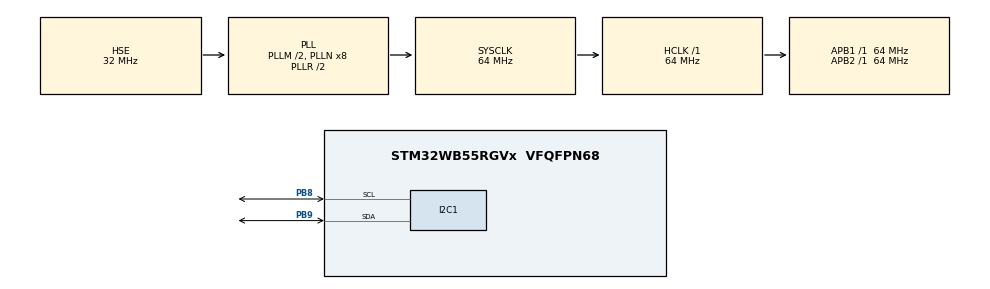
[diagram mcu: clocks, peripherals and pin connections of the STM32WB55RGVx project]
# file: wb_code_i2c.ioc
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I2C1.OwnAddress=0x13
I2C1.Timing=0x10B17DB5
Mcu.Family=STM32WB
Mcu.Name=STM32WB55RGVx
Mcu.Package=VFQFPN68
NVIC.PriorityGroup=NVIC_PRIORITYGROUP_4
OSC_IN.GPIO_Label=RCC_OSC_IN
OSC_IN.Mode=HSE-External-Oscillator
OSC_IN.Signal=RCC_OSC_IN
OSC_OUT.GPIO_Label=RCC_OSC_OUT
OSC_OUT.Mode=HSE-External-Oscillator
OSC_OUT.Signal=RCC_OSC_OUT
P-NUCLEO-WB55-NUCLEO.BUTTON=1
P-NUCLEO-WB55-NUCLEO.BUTTON2=1
P-NUCLEO-WB55-NUCLEO.BUTTON3=1
P-NUCLEO-WB55-NUCLEO.LD1=true
P-NUCLEO-WB55-NUCLEO.LD2=true
P-NUCLEO-WB55-NUCLEO.LD3=true
P-NUCLEO-WB55-NUCLEO.VCP=true
PA11.GPIO_Label=USB_DM
PA11.Signal=USB_DM
PA12.GPIO_Label=USB_DP
PA12.Signal=USB_DP
PA13.GPIO_Label=JTMS
PA13.Mode=Serial_Wire
PA13.Signal=SYS_JTMS-SWDIO
PA14.GPIO_Label=JTCK
PA14.Mode=Serial_Wire
PA14.Signal=SYS_JTCK-SWCLK
PB3.GPIO_Label=JTDO
PB3.Signal=SYS_JTDO-SWO
PB6.Signal=USART1_TX
PB7.Signal=USART1_RX
PB8.Mode=I2C
PB8.Signal=I2C1_SCL
PB9.Mode=I2C
PB9.Signal=I2C1_SDA
PC13.GPIO_Label=SYS_WKUP2
PC13.Signal=SYS_WKUP2
PC14-OSC32_IN.GPIO_Label=RCC_OSC32_IN
PC14-OSC32_IN.Mode=LSE-External-Oscillator
PC14-OSC32_IN.Signal=RCC_OSC32_IN
PC15-OSC32_OUT.GPIO_Label=RCC_OSC32_OUT
PC15-OSC32_OUT.Mode=LSE-External-Oscillator
PC15-OSC32_OUT.Signal=RCC_OSC32_OUT
ProjectManager.HeapSize=0x200
ProjectManager.StackSize=0x400
ProjectManager.TargetToolchain=STM32CubeIDE
RCC.ADCFreq_Value=64000000
RCC.AHB2CLKDivider=RCC_SYSCLK_DIV2
RCC.AHBFreq_Value=64000000
RCC.APB1Freq_Value=64000000
RCC.APB1TimFreq_Value=64000000
RCC.APB2Freq_Value=64000000
RCC.APB2TimFreq_Value=64000000
RCC.APB3Freq_Value=16000000
RCC.Cortex2_Div=SYSTICK_CLKSOURCE_HCLK_DIV8
RCC.CortexFreq_Value=64000000
RCC.HCLKFreq_Value=64000000
RCC.HSE_VALUE=32000000
RCC.HSI48_VALUE=48000000
RCC.HSI_VALUE=16000000
RCC.PLLM=RCC_PLLM_DIV2
RCC.PLLSourceVirtual=RCC_PLLSOURCE_HSE
RCC.SMPSCLockSelection=RCC_SMPSCLKSOURCE_HSI
RCC.SMPSCLockSelectionVirtual=RCC_SMPSCLKSOURCE_HSI
RCC.SMPSCLockSelectionVirtualVirtual=RCC_SMPSCLKSOURCE_HSI
RCC.SMPSDivider=1
RCC.SYSCLKFreq_VALUE=64000000
RCC.SYSCLKSource=RCC_SYSCLKSOURCE_PLLCLK
RCC.USBFreq_Value=64000000
RCC.VCOOutputFreq_Value=128000000
VP_MEMORYMAP_VS_MEMORYMAP.Mode=CurAppReg
VP_P-NUCLEO-WB55-NUCLEO_VS_BSP_COMMON.Mode=COMMON
board=P-NUCLEO-WB55-NUCLEO

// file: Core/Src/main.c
/* USER CODE BEGIN Header */
/**
  ******************************************************************************
  * @file           : main.c
  * @brief          : Main program body
  ******************************************************************************
  * @attention
  *
  * Copyright (c) 2025 STMicroelectronics.
  * All rights reserved.
  *
  * This software is licensed under terms that can be found in the LICENSE file
  * in the root directory of this software component.
  * If no LICENSE file comes with this software, it is provided AS-IS.
  *
  ******************************************************************************
  */
/* USER CODE END Header */
#include "main.h"

/* USER CODE BEGIN PTD */

  volatile uint8_t hmid = 0;
  volatile uint8_t satour = 2;
  volatile uint8_t a = 0;
  volatile uint8_t b = 2;
/* USER CODE END PTD */
uint8_t received_data = 0;
  uint8_t response_data = 0;

COM_InitTypeDef BspCOMInit;
I2C_HandleTypeDef hi2c1;

void SystemClock_Config(void);
void PeriphCommonClock_Config(void);
static void MX_GPIO_Init(void);
static void MX_I2C1_Init(void);

int main(void)
{

  /* MCU Configuration--------------------------------------------------------*/

  /* Reset of all peripherals, Initializes the Flash interface and the Systick. */
  HAL_Init();

  /* Configure the system clock */
  SystemClock_Config();

  /* Configure the peripherals common clocks */
  PeriphCommonClock_Config();

  /* Initialize all configured peripherals */
  MX_GPIO_Init();
  MX_I2C1_Init();

  /* Initialize leds */
  BSP_LED_Init(LED_BLUE);
  BSP_LED_Init(LED_GREEN);
  BSP_LED_Init(LED_RED);

  /* Initialize USER push-button, will be used to trigger an interrupt each time it's pressed.*/
  BSP_PB_Init(BUTTON_SW1, BUTTON_MODE_EXTI);
  BSP_PB_Init(BUTTON_SW2, BUTTON_MODE_EXTI);
  BSP_PB_Init(BUTTON_SW3, BUTTON_MODE_EXTI);

  /* Initialize COM1 port (115200, 8 bits (7-bit data + 1 stop bit), no parity */
  BspCOMInit.BaudRate   = 115200;
  BspCOMInit.WordLength = COM_WORDLENGTH_8B;
  BspCOMInit.StopBits   = COM_STOPBITS_1;
  BspCOMInit.Parity     = COM_PARITY_NONE;
  BspCOMInit.HwFlowCtl  = COM_HWCONTROL_NONE;
  if (BSP_COM_Init(COM1, &BspCOMInit) != BSP_ERROR_NONE)
  {
    Error_Handler();
  }

  /* Infinite loop */
  while (1)
  {

    /* USER CODE BEGIN 3 */

	  	  	 HAL_I2C_Slave_Receive(&hi2c1, &received_data, 1, HAL_MAX_DELAY);
	  	  	  	  HAL_GPIO_WritePin(GPIOB, GPIO_PIN_8, GPIO_PIN_RESET); // Mettre SCL (PB6) à LOW
	              HAL_Delay(5000); // Attendre 1 seconde
	              HAL_GPIO_WritePin(GPIOB, GPIO_PIN_8, GPIO_PIN_SET); // Relâcher SCL (PB6)
	         // Incrémenter la donnée reçue
	         response_data = received_data + 1;

	         // Renvoyer la donnée modifiée au maître
	         HAL_I2C_Slave_Transmit(&hi2c1, &response_data, 1, HAL_MAX_DELAY);
  }
  /* USER CODE END 3 */
}

void SystemClock_Config(void)
{
  RCC_OscInitTypeDef RCC_OscInitStruct = {0};
  RCC_ClkInitTypeDef RCC_ClkInitStruct = {0};

  /** Configure the main internal regulator output voltage
  */
  __HAL_PWR_VOLTAGESCALING_CONFIG(PWR_REGULATOR_VOLTAGE_SCALE1);

  /** Initializes the RCC Oscillators according to the specified parameters
  * in the RCC_OscInitTypeDef structure.
  */
  RCC_OscInitStruct.OscillatorType = RCC_OSCILLATORTYPE_HSI|RCC_OSCILLATORTYPE_HSE;
  RCC_OscInitStruct.HSEState = RCC_HSE_ON;
  RCC_OscInitStruct.HSIState = RCC_HSI_ON;
  RCC_OscInitStruct.HSICalibrationValue = RCC_HSICALIBRATION_DEFAULT;
  RCC_OscInitStruct.PLL.PLLState = RCC_PLL_ON;
  RCC_OscInitStruct.PLL.PLLSource = RCC_PLLSOURCE_HSE;
  RCC_OscInitStruct.PLL.PLLM = RCC_PLLM_DIV2;
  RCC_OscInitStruct.PLL.PLLN = 8;
  RCC_OscInitStruct.PLL.PLLP = RCC_PLLP_DIV2;
  RCC_OscInitStruct.PLL.PLLR = RCC_PLLR_DIV2;
  RCC_OscInitStruct.PLL.PLLQ = RCC_PLLQ_DIV2;
  if (HAL_RCC_OscConfig(&RCC_OscInitStruct) != HAL_OK)
  {
    Error_Handler();
  }

  /** Configure the SYSCLKSource, HCLK, PCLK1 and PCLK2 clocks dividers
  */
  RCC_ClkInitStruct.ClockType = RCC_CLOCKTYPE_HCLK4|RCC_CLOCKTYPE_HCLK2
                              |RCC_CLOCKTYPE_HCLK|RCC_CLOCKTYPE_SYSCLK
                              |RCC_CLOCKTYPE_PCLK1|RCC_CLOCKTYPE_PCLK2;
  RCC_ClkInitStruct.SYSCLKSource = RCC_SYSCLKSOURCE_PLLCLK;
  RCC_ClkInitStruct.AHBCLKDivider = RCC_SYSCLK_DIV1;
  RCC_ClkInitStruct.APB1CLKDivider = RCC_HCLK_DIV1;
  RCC_ClkInitStruct.APB2CLKDivider = RCC_HCLK_DIV1;
  RCC_ClkInitStruct.AHBCLK2Divider = RCC_SYSCLK_DIV2;
  RCC_ClkInitStruct.AHBCLK4Divider = RCC_SYSCLK_DIV1;

  if (HAL_RCC_ClockConfig(&RCC_ClkInitStruct, FLASH_LATENCY_3) != HAL_OK)
  {
    Error_Handler();
  }
}

void PeriphCommonClock_Config(void)
{
  RCC_PeriphCLKInitTypeDef PeriphClkInitStruct = {0};

  /** Initializes the peripherals clock
  */
  PeriphClkInitStruct.PeriphClockSelection = RCC_PERIPHCLK_SMPS;
  PeriphClkInitStruct.SmpsClockSelection = RCC_SMPSCLKSOURCE_HSI;
  PeriphClkInitStruct.SmpsDivSelection = RCC_SMPSCLKDIV_RANGE0;

  if (HAL_RCCEx_PeriphCLKConfig(&PeriphClkInitStruct) != HAL_OK)
  {
    Error_Handler();
  }
}

static void MX_I2C1_Init(void)
{

  hi2c1.Instance = I2C1;
  hi2c1.Init.Timing = 0x10B17DB5;
  hi2c1.Init.OwnAddress1 = 38;
  hi2c1.Init.AddressingMode = I2C_ADDRESSINGMODE_7BIT;
  hi2c1.Init.DualAddressMode = I2C_DUALADDRESS_DISABLE;
  hi2c1.Init.OwnAddress2 = 0;
  hi2c1.Init.OwnAddress2Masks = I2C_OA2_NOMASK;
  hi2c1.Init.GeneralCallMode = I2C_GENERALCALL_DISABLE;
  hi2c1.Init.NoStretchMode = I2C_NOSTRETCH_DISABLE;
  if (HAL_I2C_Init(&hi2c1) != HAL_OK)
  {
    Error_Handler();
  }

  /** Configure Analogue filter
  */
  if (HAL_I2CEx_ConfigAnalogFilter(&hi2c1, I2C_ANALOGFILTER_ENABLE) != HAL_OK)
  {
    Error_Handler();
  }

  /** Configure Digital filter
  */
  if (HAL_I2CEx_ConfigDigitalFilter(&hi2c1, 0) != HAL_OK)
  {
    Error_Handler();
  }

}

static void MX_GPIO_Init(void)
{
  GPIO_InitTypeDef GPIO_InitStruct = {0};

  /* GPIO Ports Clock Enable */
  __HAL_RCC_GPIOC_CLK_ENABLE();
  __HAL_RCC_GPIOB_CLK_ENABLE();
  __HAL_RCC_GPIOA_CLK_ENABLE();

  /*Configure GPIO pins : USB_DM_Pin USB_DP_Pin */
  GPIO_InitStruct.Pin = USB_DM_Pin|USB_DP_Pin;
  GPIO_InitStruct.Mode = GPIO_MODE_AF_PP;
  GPIO_InitStruct.Pull = GPIO_NOPULL;
  GPIO_InitStruct.Speed = GPIO_SPEED_FREQ_LOW;
  GPIO_InitStruct.Alternate = GPIO_AF10_USB;
  HAL_GPIO_Init(GPIOA, &GPIO_InitStruct);

}

void Error_Handler(void)
{
  __disable_irq();
  while (1)
  {
  }
}
